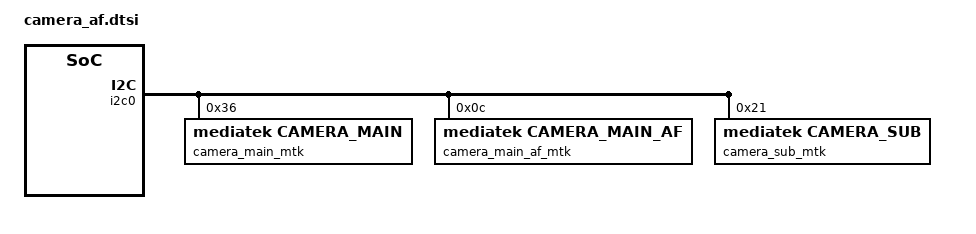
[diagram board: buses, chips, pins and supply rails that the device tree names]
/*
 * Generated by MTK SP Drv_CodeGen Version 03.13.6  for MT6580. Copyright MediaTek Inc. (C) 2013.
 * Tue Jul  3 02:03:43 2018
 * Do Not Modify the File.
 */

/*************************
 * I2C DTSI File
*************************/

&i2c0 {
	#address-cells = <1>;
	#size-cells = <0>;
	camera_main_mtk:camera_main@36 {
		compatible = "mediatek,camera_main";
		reg = <0x36>;
		status = "okay";
	};
	camera_main_af_mtk:camera_main_af@0C {
		compatible = "mediatek,camera_main_af";
		reg = <0x0C>;
		status = "okay";
	};
	camera_sub_mtk:camera_sub@21 {
		compatible = "mediatek,camera_sub";
		reg = <0x21>;
		status = "okay";
	};
};

